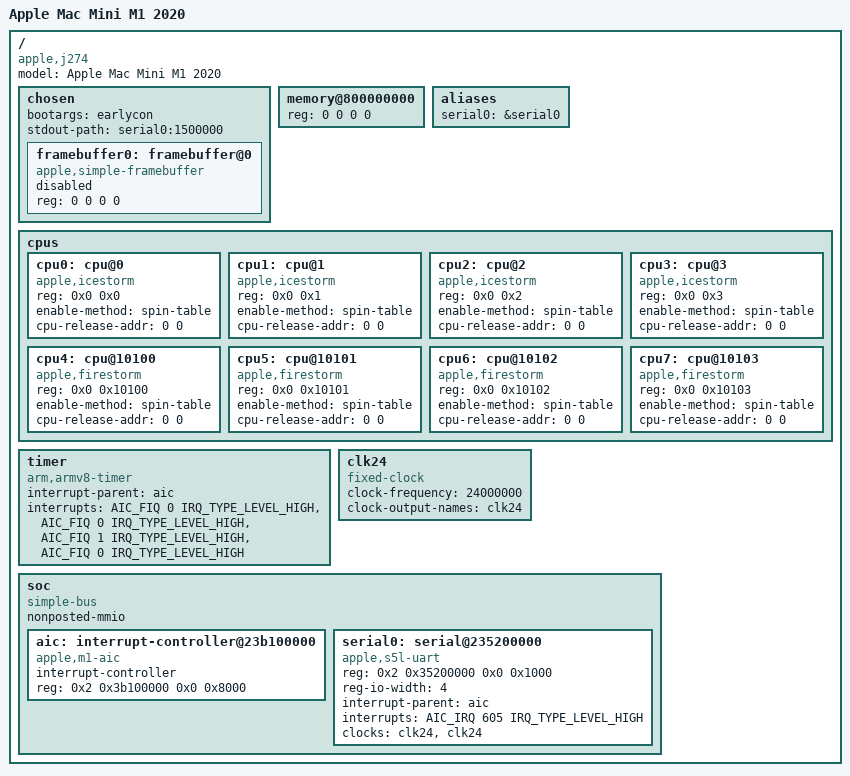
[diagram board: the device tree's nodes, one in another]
// SPDX-License-Identifier: GPL-2.0+
/*
 * Copyright 2021 Hector Martin <marcan@marcan.st>
 */

/dts-v1/;
#include <dt-bindings/interrupt-controller/apple-aic.h>
#include <dt-bindings/interrupt-controller/irq.h>

/ {
	model = "Apple Mac Mini M1 2020";
	compatible = "apple,j274", "apple,m1", "apple,arm-platform";
	#address-cells = <2>;
	#size-cells = <2>;

	chosen {
		#address-cells = <2>;
		#size-cells = <2>;
		ranges;

		bootargs = "earlycon";
		stdout-path = "serial0:1500000";

		framebuffer0: framebuffer@0 {
			compatible = "apple,simple-framebuffer", "simple-framebuffer";
			reg = <0 0 0 0>; // To be filled by loader
			// Format properties will be added by loader
			status = "disabled";
		};
	};

	memory@800000000 {
		device_type = "memory";
		reg = <0 0 0 0>; // To be filled by loader
	};

	aliases {
		serial0 = &serial0;
	};

	cpus {
		#address-cells = <2>;
		#size-cells = <0>;

		cpu0: cpu@0 {
			compatible = "apple,icestorm";
			device_type = "cpu";
			reg = <0x0 0x0>;
			enable-method = "spin-table";
			cpu-release-addr = <0 0>; // To be filled by loader
		};
		cpu1: cpu@1 {
			compatible = "apple,icestorm";
			device_type = "cpu";
			reg = <0x0 0x1>;
			enable-method = "spin-table";
			cpu-release-addr = <0 0>; // To be filled by loader
		};
		cpu2: cpu@2 {
			compatible = "apple,icestorm";
			device_type = "cpu";
			reg = <0x0 0x2>;
			enable-method = "spin-table";
			cpu-release-addr = <0 0>; // To be filled by loader
		};
		cpu3: cpu@3 {
			compatible = "apple,icestorm";
			device_type = "cpu";
			reg = <0x0 0x3>;
			enable-method = "spin-table";
			cpu-release-addr = <0 0>; // To be filled by loader
		};
		cpu4: cpu@10100 {
			compatible = "apple,firestorm";
			device_type = "cpu";
			reg = <0x0 0x10100>;
			enable-method = "spin-table";
			cpu-release-addr = <0 0>; // To be filled by loader
		};
		cpu5: cpu@10101 {
			compatible = "apple,firestorm";
			device_type = "cpu";
			reg = <0x0 0x10101>;
			enable-method = "spin-table";
			cpu-release-addr = <0 0>; // To be filled by loader
		};
		cpu6: cpu@10102 {
			compatible = "apple,firestorm";
			device_type = "cpu";
			reg = <0x0 0x10102>;
			enable-method = "spin-table";
			cpu-release-addr = <0 0>; // To be filled by loader
		};
		cpu7: cpu@10103 {
			compatible = "apple,firestorm";
			device_type = "cpu";
			reg = <0x0 0x10103>;
			enable-method = "spin-table";
			cpu-release-addr = <0 0>; // To be filled by loader
		};
	};

	timer {
		compatible = "arm,armv8-timer";
		interrupt-parent = <&aic>;
		interrupts = <AIC_FIQ 0 IRQ_TYPE_LEVEL_HIGH>,
				<AIC_FIQ 0 IRQ_TYPE_LEVEL_HIGH>,
				<AIC_FIQ 1 IRQ_TYPE_LEVEL_HIGH>,
				<AIC_FIQ 0 IRQ_TYPE_LEVEL_HIGH>;
	};

	clk24: clk24 {
		compatible = "fixed-clock";
		#clock-cells = <0>;
		clock-frequency = <24000000>;
		clock-output-names = "clk24";
	};

	soc {
		compatible = "simple-bus";
		#address-cells = <2>;
		#size-cells = <2>;
		ranges;

		nonposted-mmio;

		aic: interrupt-controller@23b100000 {
			compatible = "apple,m1-aic", "apple,aic";
			#interrupt-cells = <3>;
			interrupt-controller;
			reg = <0x2 0x3b100000 0x0 0x8000>;
		};

		serial0: serial@235200000 {
			compatible = "apple,s5l-uart";
			reg = <0x2 0x35200000 0x0 0x1000>;
			reg-io-width = <4>;
			interrupt-parent = <&aic>;
			interrupts = <AIC_IRQ 605 IRQ_TYPE_LEVEL_HIGH>;
			clocks = <&clk24>, <&clk24>;
			clock-names = "uart", "clk_uart_baud0";
		};

	};
};
